# ATSAMA5D28CLD2G register map
Vendor: Microchip Technology; Series: SAMA5D2; File version: 0
Registers are 32-bit, read-write, reset 0x0 unless marked. A register's access mark holds for its fields unless they carry their own. Offsets are from the block's base; [hi:lo] are bit positions; lines under a group give offsets from that group; {n}, {i} and the like mark numbered series; 'fields as' and 'values as' point back to an identical list.

## UDPHS — USB High Speed Device Port
Base 0xFC02C000; register names take the prefix UDPHS_
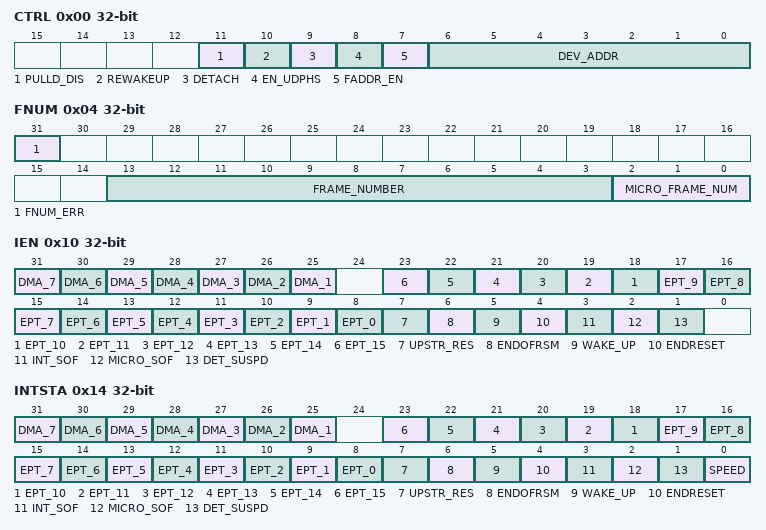
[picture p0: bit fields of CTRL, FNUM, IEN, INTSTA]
0x00 CTRL — UDPHS Control Register
  [11] PULLD_DIS — Pulldown Disable (cleared upon USB reset)
  [10] REWAKEUP — Send Remote Wakeup (cleared upon USB reset)
  [9] DETACH — Detach Command
  [8] EN_UDPHS — UDPHS Enable
  [7] FADDR_EN — Function Address Enable (cleared upon USB reset)
  [6:0] DEV_ADDR — UDPHS Address (cleared upon USB reset)
0x04 FNUM ro — UDPHS Frame Number Register
  [31] FNUM_ERR — Frame Number CRC Error (cleared upon USB reset)
  [13:3] FRAME_NUMBER — Frame Number as defined in the Packet Field Formats (cleared upon USB reset)
  [2:0] MICRO_FRAME_NUM — Microframe Number (cleared upon USB reset)
0x10 IEN — UDPHS Interrupt Enable Register
  [n+24] DMA_{n} (n=1..7) — DMA Channel {n} Interrupt Enable (cleared upon USB reset)
  [n+8] EPT_{n} (n=0..15) — Endpoint {n} Interrupt Enable (cleared upon USB reset)
  [7] UPSTR_RES — Upstream Resume Interrupt Enable (cleared upon USB reset)
  [6] ENDOFRSM — End Of Resume Interrupt Enable (cleared upon USB reset)
  [5] WAKE_UP — Wake Up CPU Interrupt Enable (cleared upon USB reset)
  [4] ENDRESET — End Of Reset Interrupt Enable (cleared upon USB reset)
  [3] INT_SOF — SOF Interrupt Enable (cleared upon USB reset)
  [2] MICRO_SOF — Micro-SOF Interrupt Enable (cleared upon USB reset)
  [1] DET_SUSPD — Suspend Interrupt Enable (cleared upon USB reset)
0x14 INTSTA ro — UDPHS Interrupt Status Register
  [n+24] DMA_{n} (n=1..7) — DMA Channel {n} Interrupt
  [n+8] EPT_{n} (n=0..15) — Endpoint {n} Interrupt (cleared upon USB reset)
  [7] UPSTR_RES — Upstream Resume Interrupt
  [6] ENDOFRSM — End Of Resume Interrupt
  [5] WAKE_UP — Wake Up CPU Interrupt
  [4] ENDRESET — End Of Reset Interrupt
  [3] INT_SOF — Start Of Frame Interrupt
  [2] MICRO_SOF — Micro Start Of Frame Interrupt
  [1] DET_SUSPD — Suspend Interrupt
  [0] SPEED — Speed Status
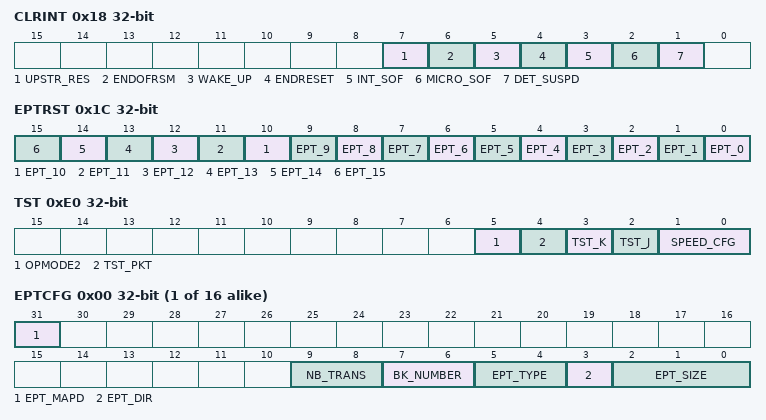
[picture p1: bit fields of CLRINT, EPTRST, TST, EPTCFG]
0x18 CLRINT wo — UDPHS Clear Interrupt Register
  [7] UPSTR_RES — Upstream Resume Interrupt Clear
  [6] ENDOFRSM — End Of Resume Interrupt Clear
  [5] WAKE_UP — Wake Up CPU Interrupt Clear
  [4] ENDRESET — End Of Reset Interrupt Clear
  [3] INT_SOF — Start Of Frame Interrupt Clear
  [2] MICRO_SOF — Micro Start Of Frame Interrupt Clear
  [1] DET_SUSPD — Suspend Interrupt Clear
0x1C EPTRST wo — UDPHS Endpoints Reset Register
  [n] EPT_{n} (n=0..15) — Endpoint {n} Reset
0xE0 TST — UDPHS Test Register
  [5] OPMODE2
  [4] TST_PKT — Test Packet Mode
  [3] TST_K — Test K Mode
  [2] TST_J — Test J Mode
  [1:0] SPEED_CFG — Speed Configuration
    0=NORMAL (Normal mode: The macro is in Full Speed mode, ready to make a High Speed identification, if the host supports it and then to automatically switch to High Speed mode.); 2=HIGH_SPEED (Force High Speed: Set this value to force the hardware to work in High Speed mode. Only for debug or test purpose.); 3=FULL_SPEED (Force Full Speed: Set this value to force the hardware to work only in Full Speed mode. In this configuration, the macro will not respond to a High Speed reset handshake.)
0xEC ADDRSIZE ro — UDPHS IP Address Size Register
  [31:0] ADDRSIZE — Peripheral Bus Address Size
{0xF0+4i} IPNAME[{i}] (i=0..1) ro — UDPHS IP Name1 Register
  [31:0] IPNAME — IP Name in ASCII Format
0xF8 FEATURES ro — UDPHS Features Register
{0x100+0x20*i} UDPHS_EPT[{i}] (i=0..15) group
  0x00 EPTCFG — UDPHS Endpoint Configuration Register (endpoint = 0)
    [31] EPT_MAPD — Endpoint Mapped (cleared upon USB reset)
    [9:8] NB_TRANS — Number Of Transaction per Microframe (cleared upon USB reset)
    [7:6] BK_NUMBER — Number of Banks (cleared upon USB reset)
      0=Zero bank, the endpoint is not mapped in memory; 1=One bank (bank 0); 2=Double bank (Ping-Pong: bank0/bank1); 3=Triple bank (bank0/bank1/bank2)
    [5:4] EPT_TYPE — Endpoint Type (cleared upon USB reset)
      0=CTRL8 (Control endpoint); 1=ISO (Isochronous endpoint); 2=BULK (Bulk endpoint); 3=INT (Interrupt endpoint)
    [3] EPT_DIR — Endpoint Direction (cleared upon USB reset)
    [2:0] EPT_SIZE — Endpoint Size (cleared upon USB reset)
      0=8 bytes; 1=16 bytes; 2=32 bytes; 3=64 bytes; 4=128 bytes; 5=256 bytes; 6=512 bytes; 7=1024 bytes
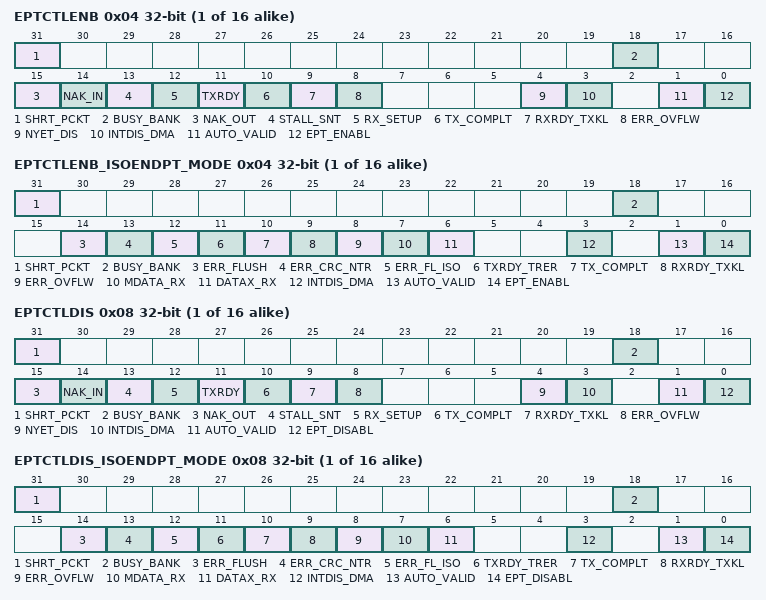
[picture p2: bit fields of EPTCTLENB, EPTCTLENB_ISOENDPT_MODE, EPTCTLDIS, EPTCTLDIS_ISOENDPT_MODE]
  0x04 EPTCTLENB wo — UDPHS Endpoint Control Enable Register (endpoint = 0)
    [31] SHRT_PCKT — Short Packet Send/Short Packet Interrupt Enable
    [18] BUSY_BANK — Busy Bank Interrupt Enable
    [15] NAK_OUT — NAKOUT Interrupt Enable
    [14] NAK_IN — NAKIN Interrupt Enable
    [13] STALL_SNT — Stall Sent Interrupt Enable
    [12] RX_SETUP — Received SETUP
    [11] TXRDY — TX Packet Ready Interrupt Enable
    [10] TX_COMPLT — Transmitted IN Data Complete Interrupt Enable
    [9] RXRDY_TXKL — Received OUT Data Interrupt Enable
    [8] ERR_OVFLW — Overflow Error Interrupt Enable
    [4] NYET_DIS — NYET Disable (Only for High Speed Bulk OUT endpoints)
    [3] INTDIS_DMA — Interrupts Disable DMA
    [1] AUTO_VALID — Packet Auto-Valid Enable
    [0] EPT_ENABL — Endpoint Enable
  0x04 EPTCTLENB_ISOENDPT_MODE wo (alternate view of EPTCTLENB) — UDPHS Endpoint Control Enable Register (endpoint = 0)
    [31] SHRT_PCKT — Short Packet Send/Short Packet Interrupt Enable
    [18] BUSY_BANK — Busy Bank Interrupt Enable
    [14] ERR_FLUSH — Bank Flush Error Interrupt Enable
    [13] ERR_CRC_NTR — ISO CRC Error/Number of Transaction Error Interrupt Enable
    [12] ERR_FL_ISO — Error Flow Interrupt Enable
    [11] TXRDY_TRER — TX Packet Ready/Transaction Error Interrupt Enable
    [10] TX_COMPLT — Transmitted IN Data Complete Interrupt Enable
    [9] RXRDY_TXKL — Received OUT Data Interrupt Enable
    [8] ERR_OVFLW — Overflow Error Interrupt Enable
    [7] MDATA_RX — MDATA Interrupt Enable (Only for high bandwidth Isochronous OUT endpoints)
    [6] DATAX_RX — DATAx Interrupt Enable (Only for high bandwidth Isochronous OUT endpoints)
    [3] INTDIS_DMA — Interrupts Disable DMA
    [1] AUTO_VALID — Packet Auto-Valid Enable
    [0] EPT_ENABL — Endpoint Enable
  0x08 EPTCTLDIS wo — UDPHS Endpoint Control Disable Register (endpoint = 0)
    [31] SHRT_PCKT — Short Packet Interrupt Disable
    [18] BUSY_BANK — Busy Bank Interrupt Disable
    [15] NAK_OUT — NAKOUT Interrupt Disable
    [14] NAK_IN — NAKIN Interrupt Disable
    [13] STALL_SNT — Stall Sent Interrupt Disable
    [12] RX_SETUP — Received SETUP Interrupt Disable
    [11] TXRDY — TX Packet Ready Interrupt Disable
    [10] TX_COMPLT — Transmitted IN Data Complete Interrupt Disable
    [9] RXRDY_TXKL — Received OUT Data Interrupt Disable
    [8] ERR_OVFLW — Overflow Error Interrupt Disable
    [4] NYET_DIS — NYET Enable (Only for High Speed Bulk OUT endpoints)
    [3] INTDIS_DMA — Interrupts Disable DMA
    [1] AUTO_VALID — Packet Auto-Valid Disable
    [0] EPT_DISABL — Endpoint Disable
  0x08 EPTCTLDIS_ISOENDPT_MODE wo (alternate view of EPTCTLDIS) — UDPHS Endpoint Control Disable Register (endpoint = 0)
    [31] SHRT_PCKT — Short Packet Interrupt Disable
    [18] BUSY_BANK — Busy Bank Interrupt Disable
    [14] ERR_FLUSH — bank flush error Interrupt Disable
    [13] ERR_CRC_NTR — ISO CRC Error/Number of Transaction Error Interrupt Disable
    [12] ERR_FL_ISO — Error Flow Interrupt Disable
    [11] TXRDY_TRER — TX Packet Ready/Transaction Error Interrupt Disable
    [10] TX_COMPLT — Transmitted IN Data Complete Interrupt Disable
    [9] RXRDY_TXKL — Received OUT Data Interrupt Disable
    [8] ERR_OVFLW — Overflow Error Interrupt Disable
    [7] MDATA_RX — MDATA Interrupt Disable (Only for High Bandwidth Isochronous OUT endpoints)
    [6] DATAX_RX — DATAx Interrupt Disable (Only for High Bandwidth Isochronous OUT endpoints)
    [3] INTDIS_DMA — Interrupts Disable DMA
    [1] AUTO_VALID — Packet Auto-Valid Disable
    [0] EPT_DISABL — Endpoint Disable
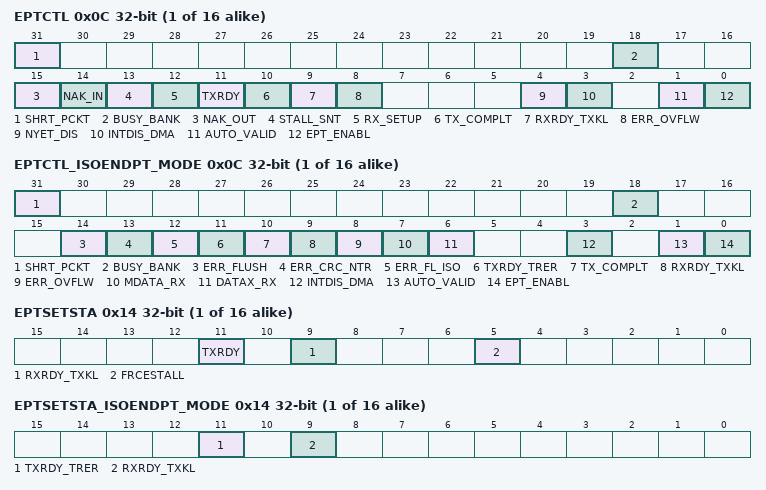
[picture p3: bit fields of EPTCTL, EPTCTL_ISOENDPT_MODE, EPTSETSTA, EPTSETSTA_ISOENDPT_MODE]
  0x0C EPTCTL ro — UDPHS Endpoint Control Register (endpoint = 0)
    [31] SHRT_PCKT — Short Packet Interrupt Enabled (cleared upon USB reset)
    [18] BUSY_BANK — Busy Bank Interrupt Enabled (cleared upon USB reset)
    [15] NAK_OUT — NAKOUT Interrupt Enabled (cleared upon USB reset)
    [14] NAK_IN — NAKIN Interrupt Enabled (cleared upon USB reset)
    [13] STALL_SNT — Stall Sent Interrupt Enabled (cleared upon USB reset)
    [12] RX_SETUP — Received SETUP Interrupt Enabled (cleared upon USB reset)
    [11] TXRDY — TX Packet Ready Interrupt Enabled (cleared upon USB reset)
    [10] TX_COMPLT — Transmitted IN Data Complete Interrupt Enabled (cleared upon USB reset)
    [9] RXRDY_TXKL — Received OUT Data Interrupt Enabled (cleared upon USB reset)
    [8] ERR_OVFLW — Overflow Error Interrupt Enabled (cleared upon USB reset)
    [4] NYET_DIS — NYET Disable (Only for High Speed Bulk OUT Endpoints) (cleared upon USB reset)
    [3] INTDIS_DMA — Interrupt Disables DMA (cleared upon USB reset)
    [1] AUTO_VALID — Packet Auto-Valid Enabled (Not for CONTROL Endpoints) (cleared upon USB reset)
    [0] EPT_ENABL — Endpoint Enable (cleared upon USB reset)
  0x0C EPTCTL_ISOENDPT_MODE ro (alternate view of EPTCTL) — UDPHS Endpoint Control Register (endpoint = 0)
    [31] SHRT_PCKT — Short Packet Interrupt Enabled (cleared upon USB reset)
    [18] BUSY_BANK — Busy Bank Interrupt Enabled (cleared upon USB reset)
    [14] ERR_FLUSH — Bank Flush Error Interrupt Enabled (cleared upon USB reset)
    [13] ERR_CRC_NTR — ISO CRC Error/Number of Transaction Error Interrupt Enabled (cleared upon USB reset)
    [12] ERR_FL_ISO — Error Flow Interrupt Enabled (cleared upon USB reset)
    [11] TXRDY_TRER — TX Packet Ready/Transaction Error Interrupt Enabled (cleared upon USB reset)
    [10] TX_COMPLT — Transmitted IN Data Complete Interrupt Enabled (cleared upon USB reset)
    [9] RXRDY_TXKL — Received OUT Data Interrupt Enabled (cleared upon USB reset)
    [8] ERR_OVFLW — Overflow Error Interrupt Enabled (cleared upon USB reset)
    [7] MDATA_RX — MDATA Interrupt Enabled (Only for High Bandwidth Isochronous OUT endpoints) (cleared upon USB reset)
    [6] DATAX_RX — DATAx Interrupt Enabled (Only for High Bandwidth Isochronous OUT endpoints) (cleared upon USB reset)
    [3] INTDIS_DMA — Interrupt Disables DMA (cleared upon USB reset)
    [1] AUTO_VALID — Packet Auto-Valid Enabled (cleared upon USB reset)
    [0] EPT_ENABL — Endpoint Enable (cleared upon USB reset)
  0x14 EPTSETSTA wo — UDPHS Endpoint Set Status Register (endpoint = 0)
    [11] TXRDY — TX Packet Ready Set
    [9] RXRDY_TXKL — KILL Bank Set (for IN Endpoint)
    [5] FRCESTALL — Stall Handshake Request Set
  0x14 EPTSETSTA_ISOENDPT_MODE wo (alternate view of EPTSETSTA) — UDPHS Endpoint Set Status Register (endpoint = 0)
    [11] TXRDY_TRER — TX Packet Ready Set
    [9] RXRDY_TXKL — KILL Bank Set (for IN Endpoint)
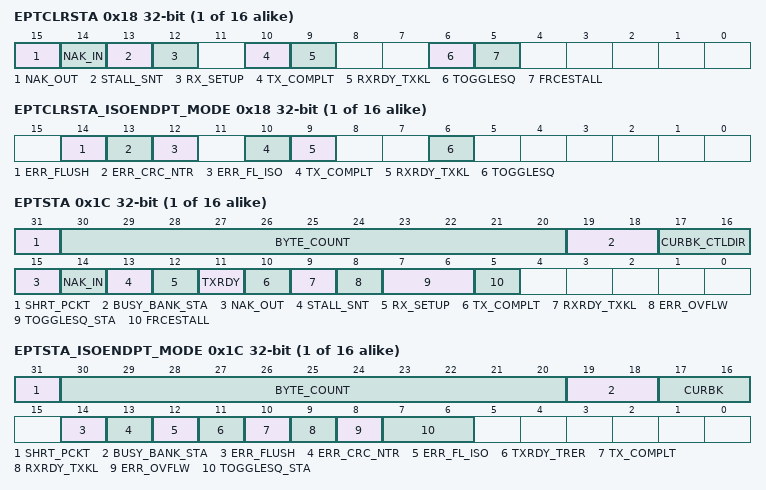
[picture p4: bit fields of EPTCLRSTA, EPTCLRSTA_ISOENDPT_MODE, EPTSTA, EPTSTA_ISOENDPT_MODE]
  0x18 EPTCLRSTA wo — UDPHS Endpoint Clear Status Register (endpoint = 0)
    [15] NAK_OUT — NAKOUT Clear
    [14] NAK_IN — NAKIN Clear
    [13] STALL_SNT — Stall Sent Clear
    [12] RX_SETUP — Received SETUP Clear
    [10] TX_COMPLT — Transmitted IN Data Complete Clear
    [9] RXRDY_TXKL — Received OUT Data Clear
    [6] TOGGLESQ — Data Toggle Clear
    [5] FRCESTALL — Stall Handshake Request Clear
  0x18 EPTCLRSTA_ISOENDPT_MODE wo (alternate view of EPTCLRSTA) — UDPHS Endpoint Clear Status Register (endpoint = 0)
    [14] ERR_FLUSH — Bank Flush Error Clear
    [13] ERR_CRC_NTR — Number of Transaction Error Clear
    [12] ERR_FL_ISO — Error Flow Clear
    [10] TX_COMPLT — Transmitted IN Data Complete Clear
    [9] RXRDY_TXKL — Received OUT Data Clear
    [6] TOGGLESQ — Data Toggle Clear
  0x1C EPTSTA ro — UDPHS Endpoint Status Register (endpoint = 0)
    [31] SHRT_PCKT — Short Packet (cleared upon USB reset)
    [30:20] BYTE_COUNT — UDPHS Byte Count (cleared upon USB reset)
    [19:18] BUSY_BANK_STA — Busy Bank Number (cleared upon USB reset)
      0=_0BUSYBANK (All banks are free); 1=_1BUSYBANK; 2=_2BUSYBANKS; 3=_3BUSYBANKS
    [17:16] CURBK_CTLDIR — Current Bank/Control Direction (cleared upon USB reset)
    [15] NAK_OUT — NAK OUT (cleared upon USB reset)
    [14] NAK_IN — NAK IN (cleared upon USB reset)
    [13] STALL_SNT — Stall Sent (cleared upon USB reset)
    [12] RX_SETUP — Received SETUP (cleared upon USB reset)
    [11] TXRDY — TX Packet Ready (cleared upon USB reset)
    [10] TX_COMPLT — Transmitted IN Data Complete (cleared upon USB reset)
    [9] RXRDY_TXKL — Received OUT Data/KILL Bank (cleared upon USB reset)
    [8] ERR_OVFLW — Overflow Error (cleared upon USB reset)
    [7:6] TOGGLESQ_STA — Toggle Sequencing (cleared upon USB reset)
      0=DATA0; 1=DATA1; 2=DATA2 (Reserved for High Bandwidth Isochronous Endpoint); 3=MDATA (Reserved for High Bandwidth Isochronous Endpoint)
    [5] FRCESTALL — Stall Handshake Request (cleared upon USB reset)
  0x1C EPTSTA_ISOENDPT_MODE ro (alternate view of EPTSTA) — UDPHS Endpoint Status Register (endpoint = 0)
    [31] SHRT_PCKT — Short Packet (cleared upon USB reset)
    [30:20] BYTE_COUNT — UDPHS Byte Count (cleared upon USB reset)
    [19:18] BUSY_BANK_STA — Busy Bank Number (cleared upon USB reset)
      values as UDPHS_EPT[0].EPTSTA.BUSY_BANK_STA
    [17:16] CURBK — Current Bank (cleared upon USB reset)
      0=BANK0 (Bank 0 (or single bank)); 1=BANK1; 2=BANK2
    [14] ERR_FLUSH — Bank Flush Error (cleared upon USB reset)
    [13] ERR_CRC_NTR — CRC ISO Error/Number of Transaction Error (cleared upon USB reset)
    [12] ERR_FL_ISO — Error Flow (cleared upon USB reset)
    [11] TXRDY_TRER — TX Packet Ready/Transaction Error (cleared upon USB reset)
    [10] TX_COMPLT — Transmitted IN Data Complete (cleared upon USB reset)
    [9] RXRDY_TXKL — Received OUT Data/KILL Bank (cleared upon USB reset)
    [8] ERR_OVFLW — Overflow Error (cleared upon USB reset)
    [7:6] TOGGLESQ_STA — Toggle Sequencing (cleared upon USB reset)
      0=DATA0; 1=DATA1; 2=DATA2 (Data2 (only for High Bandwidth Isochronous Endpoint)); 3=MDATA (MData (only for High Bandwidth Isochronous Endpoint))
{0x300+0x10*i} UDPHS_DMA[{i}] (i=0..6) group
  0x00 DMANXTDSC — UDPHS DMA Next Descriptor Address Register (channel = 0)
    [31:0] NXT_DSC_ADD — Next Descriptor Address
  0x04 DMAADDRESS — UDPHS DMA Channel Address Register (channel = 0)
    [31:0] BUFF_ADD — Buffer Address
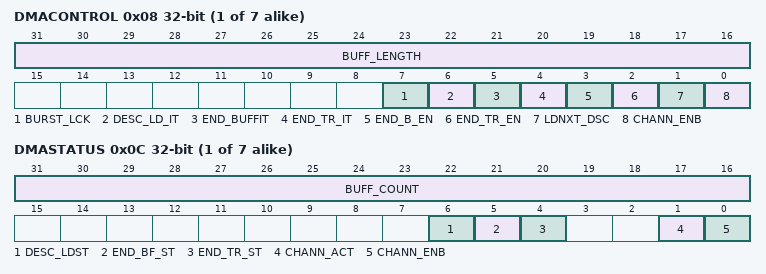
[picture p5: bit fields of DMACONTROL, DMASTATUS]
  0x08 DMACONTROL — UDPHS DMA Channel Control Register (channel = 0)
    [31:16] BUFF_LENGTH — Buffer Byte Length (Write-only)
    [7] BURST_LCK — Burst Lock Enable
    [6] DESC_LD_IT — Descriptor Loaded Interrupt Enable
    [5] END_BUFFIT — End of Buffer Interrupt Enable
    [4] END_TR_IT — End of Transfer Interrupt Enable
    [3] END_B_EN — End of Buffer Enable (Control)
    [2] END_TR_EN — End of Transfer Enable (Control)
    [1] LDNXT_DSC — Load Next Channel Transfer Descriptor Enable (Command)
    [0] CHANN_ENB — (Channel Enable Command)
  0x0C DMASTATUS — UDPHS DMA Channel Status Register (channel = 0)
    [31:16] BUFF_COUNT — Buffer Byte Count
    [6] DESC_LDST — Descriptor Loaded Status
    [5] END_BF_ST — End of Channel Buffer Status
    [4] END_TR_ST — End of Channel Transfer Status
    [1] CHANN_ACT — Channel Active Status
    [0] CHANN_ENB — Channel Enable Status
